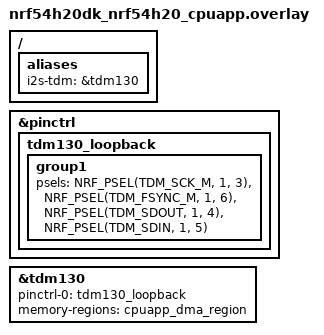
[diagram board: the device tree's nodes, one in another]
/*
 * Copyright The Zephyr Project Contributors
 *
 * SPDX-License-Identifier: Apache-2.0
 */

/* TDM_SDOUT (P1.04) must be wired to TDM_SDIN (P1.05). */

/ {
	aliases {
		i2s-tdm = &tdm130;
	};
};

&pinctrl {
	tdm130_loopback: tdm130_loopback {
		group1 {
			psels = <NRF_PSEL(TDM_SCK_M, 1, 3)>,
				<NRF_PSEL(TDM_FSYNC_M, 1, 6)>,
				<NRF_PSEL(TDM_SDOUT, 1, 4)>,
				<NRF_PSEL(TDM_SDIN, 1, 5)>;
		};
	};
};

&tdm130 {
	pinctrl-0 = <&tdm130_loopback>;
	pinctrl-names = "default";
	memory-regions = <&cpuapp_dma_region>;
	status = "okay";
};
